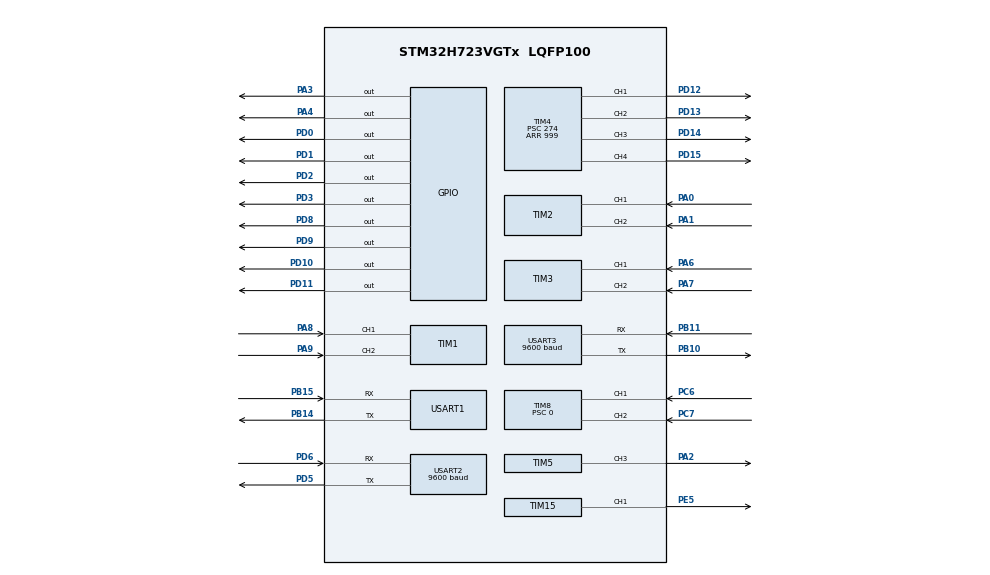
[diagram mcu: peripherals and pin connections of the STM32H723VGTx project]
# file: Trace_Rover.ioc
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CORTEX_M7.default_mode_Activation=0
Mcu.Family=STM32H7
Mcu.Name=STM32H723VGTx
Mcu.Package=LQFP100
NVIC.PriorityGroup=NVIC_PRIORITYGROUP_4
NVIC.USART1_IRQn=true\:2\:0\:true\:false\:true\:true\:true\:true
NVIC.USART2_IRQn=true\:1\:0\:true\:false\:true\:true\:true\:true
NVIC.USART3_IRQn=true\:2\:0\:true\:false\:true\:true\:true\:true
PA0.Signal=S_TIM2_CH1_ETR
PA1.Signal=S_TIM2_CH2
PA13(JTMS/SWDIO).Mode=Serial_Wire
PA13(JTMS/SWDIO).Signal=DEBUG_JTMS-SWDIO
PA14(JTCK/SWCLK).Mode=Serial_Wire
PA14(JTCK/SWCLK).Signal=DEBUG_JTCK-SWCLK
PA2.Signal=S_TIM5_CH3
PA3.Signal=GPIO_Output
PA4.Signal=GPIO_Output
PA6.Signal=S_TIM3_CH1
PA7.Signal=S_TIM3_CH2
PA8.Signal=S_TIM1_CH1
PA9.Signal=S_TIM1_CH2
PB10.Mode=Asynchronous
PB10.Signal=USART3_TX
PB11.Mode=Asynchronous
PB11.Signal=USART3_RX
PB14.Mode=Asynchronous
PB14.Signal=USART1_TX
PB15.Mode=Asynchronous
PB15.Signal=USART1_RX
PC6.Signal=S_TIM8_CH1
PC7.Signal=S_TIM8_CH2
PD0.Signal=GPIO_Output
PD1.Signal=GPIO_Output
PD10.Signal=GPIO_Output
PD11.Signal=GPIO_Output
PD12.Signal=S_TIM4_CH1
PD13.Signal=S_TIM4_CH2
PD14.Signal=S_TIM4_CH3
PD15.Signal=S_TIM4_CH4
PD2.Signal=GPIO_Output
PD3.Signal=GPIO_Output
PD5.Mode=Asynchronous
PD5.Signal=USART2_TX
PD6.Mode=Asynchronous
PD6.Signal=USART2_RX
PD8.Signal=GPIO_Output
PD9.Signal=GPIO_Output
PE5.Signal=S_TIM15_CH1
PH0-OSC_IN.Mode=HSE-External-Oscillator
PH0-OSC_IN.Signal=RCC_OSC_IN
PH1-OSC_OUT.Mode=HSE-External-Oscillator
PH1-OSC_OUT.Signal=RCC_OSC_OUT
ProjectManager.HeapSize=0x200
ProjectManager.StackSize=0x400
ProjectManager.TargetToolchain=MDK-ARM V5.32
RCC.ADCFreq_Value=50390625
RCC.APB1Freq_Value=137500000
RCC.APB2Freq_Value=137500000
RCC.APB3Freq_Value=137500000
RCC.APB4Freq_Value=137500000
RCC.CortexFreq_Value=550000000
RCC.D1PPRE=RCC_APB3_DIV2
RCC.D2PPRE1=RCC_APB1_DIV2
RCC.D2PPRE2=RCC_APB2_DIV2
RCC.D3PPRE=RCC_APB4_DIV2
RCC.DIVM1=2
RCC.DIVN1=44
RCC.DIVP1=1
RCC.HCLKFreq_Value=275000000
RCC.HPRE=RCC_HCLK_DIV2
RCC.PLLSourceVirtual=RCC_PLLSOURCE_HSE
RCC.SYSCLKFreq_VALUE=550000000
RCC.SYSCLKSource=RCC_SYSCLKSOURCE_PLLCLK
RCC.USBFreq_Value=275000000
SH.S_TIM15_CH1.0=TIM15_CH1,PWM Generation1 CH1
SH.S_TIM1_CH1.0=TIM1_CH1,Encoder_Interface
SH.S_TIM1_CH2.0=TIM1_CH2,Encoder_Interface
SH.S_TIM2_CH1_ETR.0=TIM2_CH1,Encoder_Interface
SH.S_TIM2_CH2.0=TIM2_CH2,Encoder_Interface
SH.S_TIM3_CH1.0=TIM3_CH1,Encoder_Interface
SH.S_TIM3_CH2.0=TIM3_CH2,Encoder_Interface
SH.S_TIM4_CH1.0=TIM4_CH1,PWM Generation1 CH1
SH.S_TIM4_CH2.0=TIM4_CH2,PWM Generation2 CH2
SH.S_TIM4_CH3.0=TIM4_CH3,PWM Generation3 CH3
SH.S_TIM4_CH4.0=TIM4_CH4,PWM Generation4 CH4
SH.S_TIM5_CH3.0=TIM5_CH3,PWM Generation3 CH3
SH.S_TIM8_CH1.0=TIM8_CH1,Encoder_Interface
SH.S_TIM8_CH2.0=TIM8_CH2,Encoder_Interface
TIM15.Channel-PWM\ Generation1\ CH1=TIM_CHANNEL_1
TIM15.Period=19999
TIM15.Prescaler=274
TIM4.Channel-PWM\ Generation1\ CH1=TIM_CHANNEL_1
TIM4.Channel-PWM\ Generation2\ CH2=TIM_CHANNEL_2
TIM4.Channel-PWM\ Generation3\ CH3=TIM_CHANNEL_3
TIM4.Channel-PWM\ Generation4\ CH4=TIM_CHANNEL_4
TIM4.Period=999
TIM4.Prescaler=274
TIM5.Channel-PWM\ Generation3\ CH3=TIM_CHANNEL_3
TIM5.Period=999
TIM5.Prescaler=274
TIM8.Period=65535
TIM8.Prescaler=0
USART1.VirtualMode-Asynchronous=VM_ASYNC
USART2.BaudRate=9600
USART2.VirtualMode-Asynchronous=VM_ASYNC
USART3.BaudRate=9600
USART3.VirtualMode-Asynchronous=VM_ASYNC
VP_TIM15_VS_ClockSourceINT.Mode=Internal
VP_TIM4_VS_ClockSourceINT.Mode=Internal
VP_TIM5_VS_ClockSourceINT.Mode=Internal
board=custom

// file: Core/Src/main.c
/* USER CODE BEGIN Header */
/**
  ******************************************************************************
  * @file           : main.c
  * @brief          : Main program body
  ******************************************************************************
  * @attention
  *
  * Copyright (c) 2026 STMicroelectronics.
  * All rights reserved.
  *
  * This software is licensed under terms that can be found in the LICENSE file
  * in the root directory of this software component.
  * If no LICENSE file comes with this software, it is provided AS-IS.
  *
  ******************************************************************************
  */
/* USER CODE END Header */
#include "main.h"
#include "tim.h"
#include "usart.h"
#include "gpio.h"

/* USER CODE BEGIN Includes */
#include "tasks.h"
/* USER CODE END Includes */

void SystemClock_Config(void);

int main(void)
{

  /* MCU Configuration--------------------------------------------------------*/

  /* Reset of all peripherals, Initializes the Flash interface and the Systick. */
  HAL_Init();

  /* Configure the system clock */
  SystemClock_Config();

  /* Initialize all configured peripherals */
  MX_GPIO_Init();
  MX_TIM1_Init();
  MX_TIM2_Init();
  MX_TIM3_Init();
  MX_TIM4_Init();
  MX_TIM5_Init();
  MX_TIM8_Init();
  MX_TIM15_Init();
  MX_USART1_UART_Init();
  MX_USART2_UART_Init();
  MX_USART3_UART_Init();
  /* USER CODE BEGIN 2 */
  tasks_init();

  /* USER CODE END 2 */

  /* Infinite loop */
  /* USER CODE BEGIN WHILE */
  while (1)
  {
    tasks_run();

    /* USER CODE END WHILE */

  }
}

void SystemClock_Config(void)
{
  RCC_OscInitTypeDef RCC_OscInitStruct = {0};
  RCC_ClkInitTypeDef RCC_ClkInitStruct = {0};

  /** Supply configuration update enable
  */
  HAL_PWREx_ConfigSupply(PWR_LDO_SUPPLY);

  /** Configure the main internal regulator output voltage
  */
  __HAL_PWR_VOLTAGESCALING_CONFIG(PWR_REGULATOR_VOLTAGE_SCALE0);

  while(!__HAL_PWR_GET_FLAG(PWR_FLAG_VOSRDY)) {}

  /** Initializes the RCC Oscillators according to the specified parameters
  * in the RCC_OscInitTypeDef structure.
  */
  RCC_OscInitStruct.OscillatorType = RCC_OSCILLATORTYPE_HSE;
  RCC_OscInitStruct.HSEState = RCC_HSE_ON;
  RCC_OscInitStruct.PLL.PLLState = RCC_PLL_ON;
  RCC_OscInitStruct.PLL.PLLSource = RCC_PLLSOURCE_HSE;
  RCC_OscInitStruct.PLL.PLLM = 2;
  RCC_OscInitStruct.PLL.PLLN = 44;
  RCC_OscInitStruct.PLL.PLLP = 1;
  RCC_OscInitStruct.PLL.PLLQ = 2;
  RCC_OscInitStruct.PLL.PLLR = 2;
  RCC_OscInitStruct.PLL.PLLRGE = RCC_PLL1VCIRANGE_3;
  RCC_OscInitStruct.PLL.PLLVCOSEL = RCC_PLL1VCOWIDE;
  RCC_OscInitStruct.PLL.PLLFRACN = 0;
  if (HAL_RCC_OscConfig(&RCC_OscInitStruct) != HAL_OK)
  {
    Error_Handler();
  }

  /** Initializes the CPU, AHB and APB buses clocks
  */
  RCC_ClkInitStruct.ClockType = RCC_CLOCKTYPE_HCLK|RCC_CLOCKTYPE_SYSCLK
                              |RCC_CLOCKTYPE_PCLK1|RCC_CLOCKTYPE_PCLK2
                              |RCC_CLOCKTYPE_D3PCLK1|RCC_CLOCKTYPE_D1PCLK1;
  RCC_ClkInitStruct.SYSCLKSource = RCC_SYSCLKSOURCE_PLLCLK;
  RCC_ClkInitStruct.SYSCLKDivider = RCC_SYSCLK_DIV1;
  RCC_ClkInitStruct.AHBCLKDivider = RCC_HCLK_DIV2;
  RCC_ClkInitStruct.APB3CLKDivider = RCC_APB3_DIV2;
  RCC_ClkInitStruct.APB1CLKDivider = RCC_APB1_DIV2;
  RCC_ClkInitStruct.APB2CLKDivider = RCC_APB2_DIV2;
  RCC_ClkInitStruct.APB4CLKDivider = RCC_APB4_DIV2;

  if (HAL_RCC_ClockConfig(&RCC_ClkInitStruct, FLASH_LATENCY_3) != HAL_OK)
  {
    Error_Handler();
  }
}

void Error_Handler(void)
{
  __disable_irq();
  while (1)
  {
  }
}
